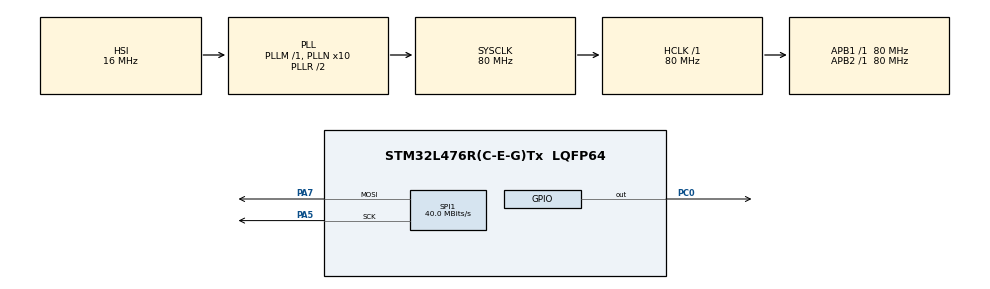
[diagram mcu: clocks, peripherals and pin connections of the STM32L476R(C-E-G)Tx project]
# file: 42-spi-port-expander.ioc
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Mcu.Family=STM32L4
Mcu.Name=STM32L476R(C-E-G)Tx
Mcu.Package=LQFP64
NVIC.PriorityGroup=NVIC_PRIORITYGROUP_4
PA5.Mode=TX_Only_Simplex_Unidirect_Master
PA5.Signal=SPI1_SCK
PA7.Mode=TX_Only_Simplex_Unidirect_Master
PA7.Signal=SPI1_MOSI
PC0.Signal=GPIO_Output
ProjectManager.HeapSize=0x200
ProjectManager.StackSize=0x400
ProjectManager.TargetToolchain=STM32CubeIDE
RCC.ADCFreq_Value=64000000
RCC.AHBFreq_Value=80000000
RCC.APB1Freq_Value=80000000
RCC.APB1TimFreq_Value=80000000
RCC.APB2Freq_Value=80000000
RCC.APB2TimFreq_Value=80000000
RCC.CortexFreq_Value=80000000
RCC.HCLKFreq_Value=80000000
RCC.HSE_VALUE=8000000
RCC.HSI_VALUE=16000000
RCC.LSE_VALUE=32768
RCC.MSI_VALUE=4000000
RCC.PLLN=10
RCC.PLLSourceVirtual=RCC_PLLSOURCE_HSI
RCC.PREFETCH_ENABLE=1
RCC.SYSCLKFreq_VALUE=80000000
RCC.SYSCLKSource=RCC_SYSCLKSOURCE_PLLCLK
RCC.USBFreq_Value=64000000
RCC.VCOOutputFreq_Value=160000000
SPI1.CalculateBaudRate=40.0 MBits/s
SPI1.DataSize=SPI_DATASIZE_8BIT
SPI1.Direction=SPI_DIRECTION_2LINES
SPI1.Mode=SPI_MODE_MASTER
SPI1.NSSPMode=SPI_NSS_PULSE_DISABLE
SPI1.VirtualType=VM_MASTER
board=NUCLEO-L476RG

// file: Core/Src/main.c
/* USER CODE BEGIN Header */
/**
  ******************************************************************************
  * @file           : main.c
  * @brief          : Main program body
  ******************************************************************************
  * @attention
  *
  * Copyright (c) 2025 STMicroelectronics.
  * All rights reserved.
  *
  * This software is licensed under terms that can be found in the LICENSE file
  * in the root directory of this software component.
  * If no LICENSE file comes with this software, it is provided AS-IS.
  *
  ******************************************************************************
  */
/* USER CODE END Header */
#include "main.h"

/* USER CODE BEGIN Includes */

//Device Address, 0x20, for 7-bit
//Read/Write for 1-bit, Read is 1, Write is 0
//0x20 shift left for 7-bit and Write = 0 for 1-bit
#define Device_Address (0x20 << 1)
#define IODIRA 0x00    //IO configure address
#define MCP_GPIOA 0x12    //Port A address
#define CS_Pin GPIO_PIN_0    //CS, chip enable pin
#define CS_Port GPIOC    //CS, chip enable port

/* USER CODE END Includes */

SPI_HandleTypeDef hspi1;

void SystemClock_Config(void);
static void MX_GPIO_Init(void);
static void MX_SPI1_Init(void);

/* USER CODE BEGIN 0 */

void SendData(uint8_t reg_addr, uint8_t data) {
  uint8_t buffer[3];
  buffer[0] = Device_Address;    //SPI address
  buffer[1] = reg_addr;    //register address
  buffer[2] = data;    //write data

  HAL_GPIO_WritePin(CS_Port, CS_Pin, GPIO_PIN_RESET);    //CS pin = 0, chip enabled

  HAL_SPI_Transmit(&hspi1, buffer, 3, HAL_MAX_DELAY);    //send command

  HAL_GPIO_WritePin(CS_Port, CS_Pin, GPIO_PIN_SET);    //CS pin = 1, chip disabled
}

/* USER CODE END 0 */

int main(void)
{

  /* MCU Configuration--------------------------------------------------------*/

  /* Reset of all peripherals, Initializes the Flash interface and the Systick. */
  HAL_Init();

  /* Configure the system clock */
  SystemClock_Config();

  /* Initialize all configured peripherals */
  MX_GPIO_Init();
  MX_SPI1_Init();
  /* USER CODE BEGIN 2 */

  HAL_SPI_Init(&hspi1);    //SPI initialize

  //IODIRA 0x00, set the port A input or output direction
  //0xFE, FE is "0b1111_1110", 1 for input, 0 for output
  //GPA1 to GPA7 are input, GPA0 is output
  SendData(IODIRA, 0xFE);    //configure output

  /* USER CODE END 2 */

  /* Infinite loop */
  /* USER CODE BEGIN WHILE */
  while (1)
  {
    //GPIOA address is 0x12
	SendData(MCP_GPIOA, 0x01);    //LED On
	HAL_Delay(1000);
	SendData(MCP_GPIOA, 0x00);    //LED Off
	HAL_Delay(1000);
    /* USER CODE END WHILE */

  }
}

void SystemClock_Config(void)
{
  RCC_OscInitTypeDef RCC_OscInitStruct = {0};
  RCC_ClkInitTypeDef RCC_ClkInitStruct = {0};

  /** Configure the main internal regulator output voltage
  */
  if (HAL_PWREx_ControlVoltageScaling(PWR_REGULATOR_VOLTAGE_SCALE1) != HAL_OK)
  {
    Error_Handler();
  }

  /** Initializes the RCC Oscillators according to the specified parameters
  * in the RCC_OscInitTypeDef structure.
  */
  RCC_OscInitStruct.OscillatorType = RCC_OSCILLATORTYPE_HSI;
  RCC_OscInitStruct.HSIState = RCC_HSI_ON;
  RCC_OscInitStruct.HSICalibrationValue = RCC_HSICALIBRATION_DEFAULT;
  RCC_OscInitStruct.PLL.PLLState = RCC_PLL_ON;
  RCC_OscInitStruct.PLL.PLLSource = RCC_PLLSOURCE_HSI;
  RCC_OscInitStruct.PLL.PLLM = 1;
  RCC_OscInitStruct.PLL.PLLN = 10;
  RCC_OscInitStruct.PLL.PLLP = RCC_PLLP_DIV7;
  RCC_OscInitStruct.PLL.PLLQ = RCC_PLLQ_DIV2;
  RCC_OscInitStruct.PLL.PLLR = RCC_PLLR_DIV2;
  if (HAL_RCC_OscConfig(&RCC_OscInitStruct) != HAL_OK)
  {
    Error_Handler();
  }

  /** Initializes the CPU, AHB and APB buses clocks
  */
  RCC_ClkInitStruct.ClockType = RCC_CLOCKTYPE_HCLK|RCC_CLOCKTYPE_SYSCLK
                              |RCC_CLOCKTYPE_PCLK1|RCC_CLOCKTYPE_PCLK2;
  RCC_ClkInitStruct.SYSCLKSource = RCC_SYSCLKSOURCE_PLLCLK;
  RCC_ClkInitStruct.AHBCLKDivider = RCC_SYSCLK_DIV1;
  RCC_ClkInitStruct.APB1CLKDivider = RCC_HCLK_DIV1;
  RCC_ClkInitStruct.APB2CLKDivider = RCC_HCLK_DIV1;

  if (HAL_RCC_ClockConfig(&RCC_ClkInitStruct, FLASH_LATENCY_4) != HAL_OK)
  {
    Error_Handler();
  }
}

static void MX_SPI1_Init(void)
{

  /* SPI1 parameter configuration*/
  hspi1.Instance = SPI1;
  hspi1.Init.Mode = SPI_MODE_MASTER;
  hspi1.Init.Direction = SPI_DIRECTION_2LINES;
  hspi1.Init.DataSize = SPI_DATASIZE_8BIT;
  hspi1.Init.CLKPolarity = SPI_POLARITY_LOW;
  hspi1.Init.CLKPhase = SPI_PHASE_1EDGE;
  hspi1.Init.NSS = SPI_NSS_SOFT;
  hspi1.Init.BaudRatePrescaler = SPI_BAUDRATEPRESCALER_2;
  hspi1.Init.FirstBit = SPI_FIRSTBIT_MSB;
  hspi1.Init.TIMode = SPI_TIMODE_DISABLE;
  hspi1.Init.CRCCalculation = SPI_CRCCALCULATION_DISABLE;
  hspi1.Init.CRCPolynomial = 7;
  hspi1.Init.CRCLength = SPI_CRC_LENGTH_DATASIZE;
  hspi1.Init.NSSPMode = SPI_NSS_PULSE_DISABLE;
  if (HAL_SPI_Init(&hspi1) != HAL_OK)
  {
    Error_Handler();
  }

}

static void MX_GPIO_Init(void)
{
  GPIO_InitTypeDef GPIO_InitStruct = {0};

  /* GPIO Ports Clock Enable */
  __HAL_RCC_GPIOC_CLK_ENABLE();
  __HAL_RCC_GPIOA_CLK_ENABLE();

  /*Configure GPIO pin Output Level */
  HAL_GPIO_WritePin(GPIOC, GPIO_PIN_0, GPIO_PIN_RESET);

  /*Configure GPIO pin : PC0 */
  GPIO_InitStruct.Pin = GPIO_PIN_0;
  GPIO_InitStruct.Mode = GPIO_MODE_OUTPUT_PP;
  GPIO_InitStruct.Pull = GPIO_NOPULL;
  GPIO_InitStruct.Speed = GPIO_SPEED_FREQ_LOW;
  HAL_GPIO_Init(GPIOC, &GPIO_InitStruct);

}

void Error_Handler(void)
{
  __disable_irq();
  while (1)
  {
  }
}
